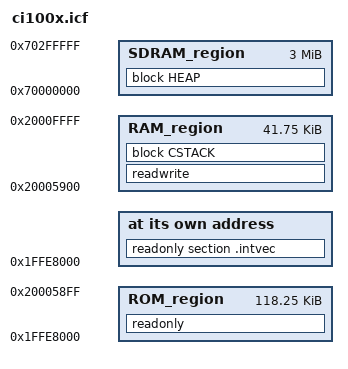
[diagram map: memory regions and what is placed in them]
/*###ICF### Section handled by ICF editor, don't touch! ****/
 
/*-Specials-*/
define symbol __ICFEDIT_intvec_start__ = 0x1FFE8000;
/*-Memory Regions-*/
define symbol __ICFEDIT_region_ROM_start__    = 0x1FFE8000;//ROM max 
define symbol __ICFEDIT_region_ROM_end__      = 0x200058FF;
define symbol __ICFEDIT_region_RAM_start__    = 0x20005900;//RAM max 
define symbol __ICFEDIT_region_RAM_end__      = 0x2000FFFF;

define symbol __ICFEDIT_region_SDRAM_start__    = 0x70000000;
define symbol __ICFEDIT_region_SDRAM_end__      = 0x702FFFFF;//HEAP 3*1024*1024MB

/*-Sizes-*/
define symbol __ICFEDIT_size_cstack__ = 0x2000;  //stack max 8kB
define symbol __ICFEDIT_size_heap__   = 0x300000;//heap  max 5MB 
/**** End of ICF editor section. ###ICF###*/


define memory mem with size = 4G;
define region ROM_region      = mem:[from __ICFEDIT_region_ROM_start__   to __ICFEDIT_region_ROM_end__];
define region RAM_region      = mem:[from __ICFEDIT_region_RAM_start__   to __ICFEDIT_region_RAM_end__];
define region SDRAM_region    = mem:[from __ICFEDIT_region_SDRAM_start__ to __ICFEDIT_region_SDRAM_end__];

define block CSTACK    with alignment = 8, size = __ICFEDIT_size_cstack__   { };
define block HEAP      with alignment = 8, size = __ICFEDIT_size_heap__     { };

initialize by copy { readwrite };
do not initialize  { section .noinit };

place at address mem:__ICFEDIT_intvec_start__ { readonly section .intvec };

place in ROM_region   { readonly };
place in RAM_region   { readwrite,
                        block CSTACK};
place in SDRAM_region { block HEAP };	
